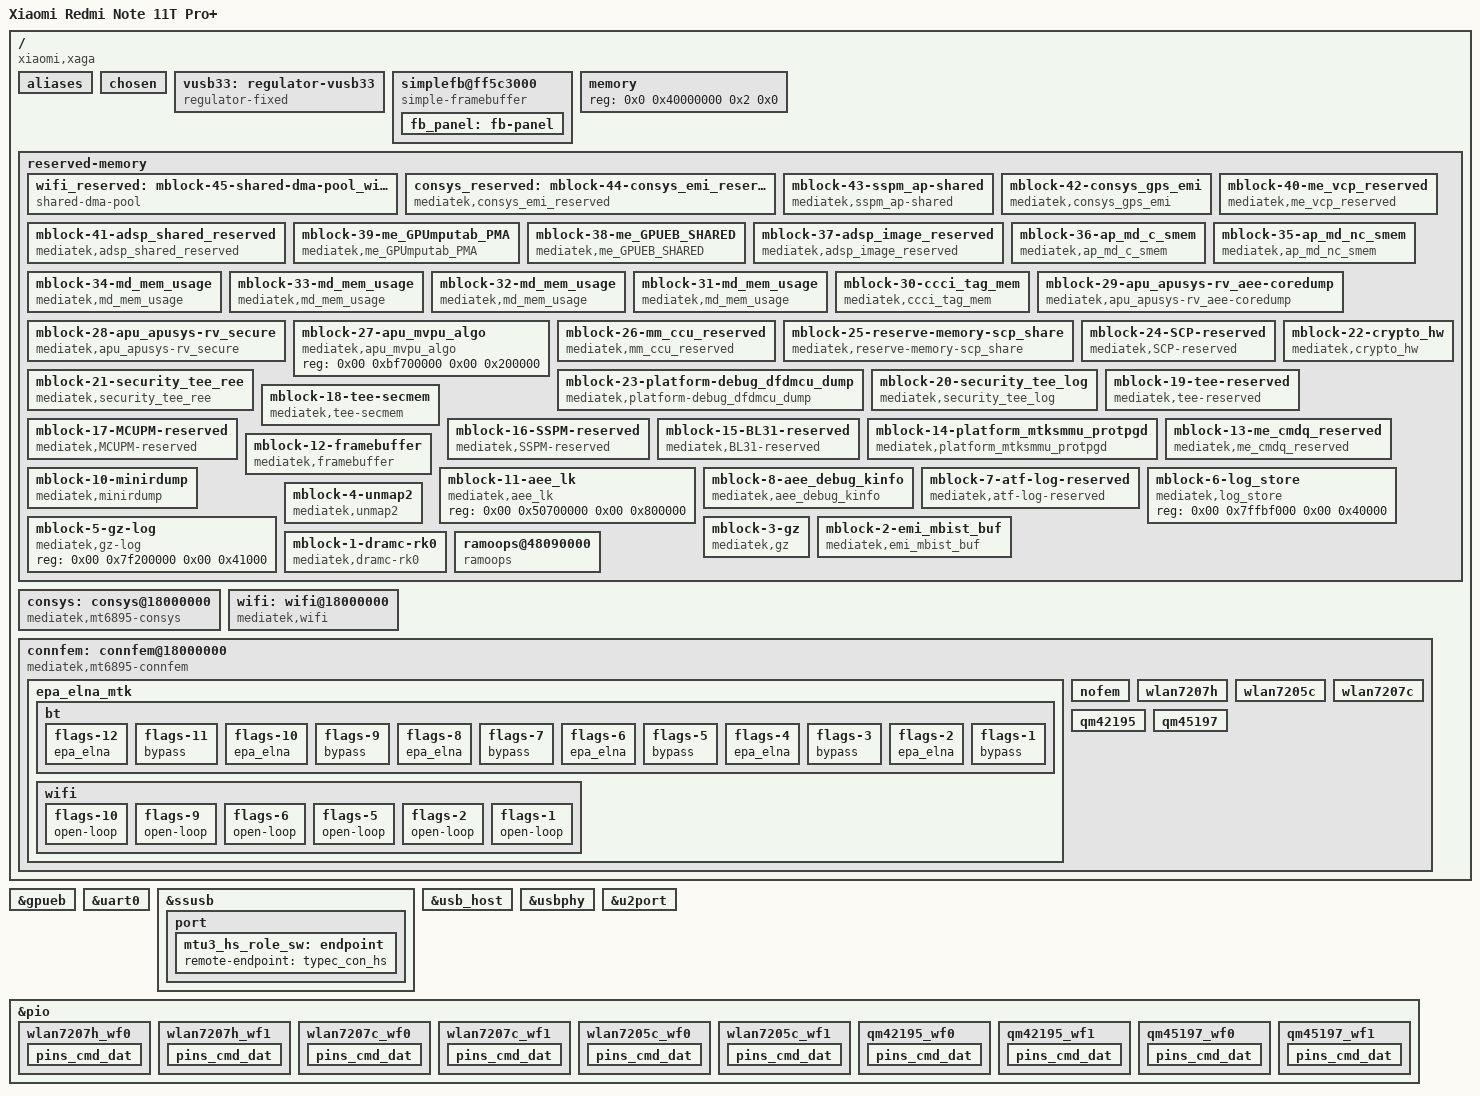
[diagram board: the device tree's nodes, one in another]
// SPDX-License-Identifier: GPL-2.0 OR MIT
/*
 * MT6895 (MediaTek Dimensity 8100) Xiaomi Redmi Note 11T Pro+ board
 *
 * Codename: xaga
 */

/dts-v1/;
#include "mt6895.dtsi"
#include <dt-bindings/input/input.h>
#include <dt-bindings/gpio/gpio.h>

/ {
	model = "Xiaomi Redmi Note 11T Pro+";
	chassis-type = "handset";
	compatible = "xiaomi,xaga", "mediatek,mt6895";

	#address-cells = <2>;
	#size-cells = <2>;

	aliases {
		serial0 = &uart0;
		/* match stock bus numbering so mt6375 etc. land on i2c-5 */
		i2c1 = &i2c1;
		i2c5 = &i2c5;
		i2c6 = &i2c6;
		i2c7 = &i2c7;
	};

	chosen {
		/*
		 * XAGA cmdline: setup.c re-reads /chosen/bootargs from THIS
		 * embedded DTB (early_init_dt_scan_chosen) because LK passes its
		 * own baked-in cmdline (setup_machine_fdt captured it before the
		 * DTB override) and ignores boot.img / vendor_boot cmdlines.
		 * printk.devkmsg=on: /dev/kmsg writes default to a 10-per-5s
		 * ratelimit that was silently dropping cinit's bursty GPT/diag
		 * output (also patched in kernel/printk/printk.c default).
		 * NOTE: console=ttyGS0 is DELIBERATELY absent — its CON_PRINTBUFFER
		 * console kept replaying the whole ring (USB re-enumeration),
		 * looping the log and stalling boot. The cinit shell still works
		 * (it writes directly to /dev/ttyGS0, no console param needed).
		 */
		bootargs = "8250.nr_uarts=4 clk_ignore_unused console=tty0 printk.devkmsg=on log_buf_len=2M";
		/*
		 * LK injects this tag into its FDT; our embedded-DTB override would
		 * lose it. Values dumped from the working Android device:
		 * struct tag_videolfb { u64 fb_base; u32 islcmfound; u32 fps;
		 *                      u32 vram; char lcmname[]; } (LE)
		 * fb_base=0xfe14f000 (framebuffer region start), islcmfound=1,
		 * fps=6060 (x100), vram=0x1eb0000, lcmname="l16_36_02_0b_dsc_vdo_lcm_drv".
		 * Without it, mtk_crtc_fill_fb_para() fails and the LK framebuffer is
		 * never inserted into the display IOMMU -> OVL fetch fault -> RDMA
		 * underflow -> display pipeline stalls after the LK frame.
		 */
		atag,videolfb = [00 f0 14 fe 00 00 00 00 01 00 00 00 ac 17 00 00
				 00 00 eb 01 6c 31 36 5f 33 36 5f 30 32 5f 30 62
				 5f 64 73 63 5f 76 64 6f 5f 6c 63 6d 5f 64 72 76
				 00 60 ff 50];
	};

	/* USB gadget 3.3V rail (mtu3 requires vusb33-supply; LK powers it) */
	vusb33: regulator-vusb33 {
		compatible = "regulator-fixed";
		regulator-name = "vusb33";
		regulator-min-microvolt = <3300000>;
		regulator-max-microvolt = <3300000>;
		regulator-always-on;
	};

	/*
	 * simple-framebuffer left behind by LK. Placed at root level (not under
	 * /chosen) because LK rewrites /chosen and would drop it.
	 * Address = the actual LK scanout layer (mt_disp_config_fb_layer =
	 * 0xff5c3000), which sits inside the reserved mblock-12-framebuffer
	 * region (0xfe14f000..0xfffff000). fbcon draws into the live LK buffer.
	 */
	simplefb@ff5c3000 {
		compatible = "simple-framebuffer";
		/* frame = stride(4352) * height(2460) = 0xa35c00; stays inside the
		 * no-map mblock-12-framebuffer region (0xfe14f000..0xfffff000) */
		reg = <0x0 0xff5c3000 0x0 0xa3c000>;
		width = <1080>;
		height = <2460>;
		stride = <(1088 * 4)>;
		format = "a8r8g8b8";
		panel = <&fb_panel>;

		fb_panel: fb-panel {
			width-mm = <75>;
			height-mm = <166>;
		};
	};

	memory {
		device_type = "memory";
		reg = <0x0 0x40000000 0x2 0x0>;
	};

	reserved-memory {
		#address-cells = <2>;
		#size-cells = <2>;
		ranges;

		/*
		 * Full MT6895 reserved-memory layout, taken verbatim from the
		 * live device tree (/sys/firmware/fdt) of the running stock
		 * Android build. These regions are owned by ATF/TEE/SCP/SSPM,
		 * modem, GPU and the display; the kernel MUST NOT allocate from
		 * them or early boot crashes on memory corruption.
		 */

		wifi_reserved: mblock-45-shared-dma-pool_wifi-reserve-memory_dma {
			reg = <0x00 0xbd000000 0x00 0x1400000>;
			no-map;
			compatible = "shared-dma-pool";
		};
		consys_reserved: mblock-44-consys_emi_reserved {
			reg = <0x00 0x8e500000 0x00 0x800000>;
			no-map;
			compatible = "mediatek,consys_emi_reserved";
		};
		mblock-43-sspm_ap-shared {
			reg = <0x00 0x7c4f0000 0x00 0x110000>;
			no-map;
			compatible = "mediatek,sspm_ap-shared";
		};
		mblock-42-consys_gps_emi {
			reg = <0x00 0x7cf00000 0x00 0x100000>;
			no-map;
			compatible = "mediatek,consys_gps_emi";
		};
		mblock-41-adsp_shared_reserved {
			reg = <0x00 0xf8000000 0x00 0x660000>;
			no-map;
			compatible = "mediatek,adsp_shared_reserved";
		};
		mblock-40-me_vcp_reserved {
			reg = <0x00 0xbee00000 0x00 0x800000>;
			no-map;
			compatible = "mediatek,me_vcp_reserved";
		};
		mblock-39-me_GPUmputab_PMA {
			reg = <0x00 0x78c00000 0x00 0x1400000>;
			no-map;
			compatible = "mediatek,me_GPUmputab_PMA";
		};
		mblock-38-me_GPUEB_SHARED {
			reg = <0x00 0x7c600000 0x00 0x200000>;
			no-map;
			compatible = "mediatek,me_GPUEB_SHARED";
		};
		mblock-37-adsp_image_reserved {
			reg = <0x00 0x7a000000 0x00 0x1230000>;
			no-map;
			compatible = "mediatek,adsp_image_reserved";
		};
		mblock-36-ap_md_c_smem {
			reg = <0x00 0x8a000000 0x00 0x2360000>;
			no-map;
			compatible = "mediatek,ap_md_c_smem";
		};
		mblock-35-ap_md_nc_smem {
			reg = <0x00 0x8e000000 0x00 0x120000>;
			no-map;
			compatible = "mediatek,ap_md_nc_smem";
		};
		mblock-34-md_mem_usage {
			reg = <0x00 0xed6e0000 0x00 0x920000>;
			no-map;
			compatible = "mediatek,md_mem_usage";
		};
		mblock-33-md_mem_usage {
			reg = <0x00 0xd4000000 0x00 0x7870000>;
			no-map;
			compatible = "mediatek,md_mem_usage";
		};
		mblock-32-md_mem_usage {
			reg = <0x00 0xd3000000 0x00 0x240000>;
			no-map;
			compatible = "mediatek,md_mem_usage";
		};
		mblock-31-md_mem_usage {
			reg = <0x00 0xd0000000 0x00 0x2710000>;
			no-map;
			compatible = "mediatek,md_mem_usage";
		};
		mblock-30-ccci_tag_mem {
			reg = <0x00 0xbf6f0000 0x00 0x10000>;
			no-map;
			compatible = "mediatek,ccci_tag_mem";
		};
		mblock-29-apu_apusys-rv_aee-coredump {
			reg = <0x00 0x8ed90000 0x00 0x270000>;
			no-map;
			compatible = "mediatek,apu_apusys-rv_aee-coredump";
		};
		mblock-28-apu_apusys-rv_secure {
			reg = <0x00 0x8f900000 0x00 0x700000>;
			no-map;
			compatible = "mediatek,apu_apusys-rv_secure";
		};
		mblock-27-apu_mvpu_algo {
			reg = <0x00 0xbf700000 0x00 0x200000>;
			compatible = "mediatek,apu_mvpu_algo";
		};
		mblock-26-mm_ccu_reserved {
			reg = <0x00 0x80000000 0x00 0x100000>;
			no-map;
			compatible = "mediatek,mm_ccu_reserved";
		};
		mblock-25-reserve-memory-scp_share {
			reg = <0x00 0x8f000000 0x00 0x6a2000>;
			no-map;
			compatible = "mediatek,reserve-memory-scp_share";
		};
		mblock-24-SCP-reserved {
			reg = <0x00 0xbf900000 0x00 0x500000>;
			no-map;
			compatible = "mediatek,SCP-reserved";
		};
		mblock-23-platform-debug_dfdmcu_dump {
			reg = <0x00 0xfd000000 0x00 0x280000>;
			no-map;
			compatible = "mediatek,platform-debug_dfdmcu_dump";
		};
		mblock-22-crypto_hw {
			reg = <0x00 0x48401000 0x00 0x1000>;
			no-map;
			compatible = "mediatek,crypto_hw";
		};
		mblock-21-security_tee_ree {
			reg = <0x02 0x3f000000 0x00 0xc00000>;
			no-map;
			compatible = "mediatek,security_tee_ree";
		};
		mblock-20-security_tee_log {
			reg = <0x02 0x3fc00000 0x00 0x20000>;
			no-map;
			compatible = "mediatek,security_tee_log";
		};
		mblock-19-tee-reserved {
			reg = <0x00 0x70000000 0x00 0x6000000>;
			no-map;
			compatible = "mediatek,tee-reserved";
		};
		mblock-18-tee-secmem {
			reg = <0x00 0x7c800000 0x00 0x700000>;
			no-map;
			compatible = "mediatek,tee-secmem";
		};
		mblock-17-MCUPM-reserved {
			reg = <0x00 0x7f300000 0x00 0x100000>;
			no-map;
			compatible = "mediatek,MCUPM-reserved";
		};
		mblock-16-SSPM-reserved {
			reg = <0x00 0x7fe3f000 0x00 0x180000>;
			no-map;
			compatible = "mediatek,SSPM-reserved";
		};
		mblock-15-BL31-reserved {
			reg = <0x00 0x48200000 0x00 0x200000>;
			no-map;
			compatible = "mediatek,BL31-reserved";
		};
		mblock-14-platform_mtksmmu_protpgd {
			reg = <0x00 0x7d000000 0x00 0x2200000>;
			no-map;
			compatible = "mediatek,platform_mtksmmu_protpgd";
		};
		mblock-13-me_cmdq_reserved {
			reg = <0x02 0x3fe00000 0x00 0x100000>;
			no-map;
			compatible = "mediatek,me_cmdq_reserved";
		};
		mblock-12-framebuffer {
			reg = <0x00 0xfe14f000 0x00 0x1eb0000>;
			/*
			 * no-map: this region (which contains the live LK scanout
			 * framebuffer at 0xff5c3000) must be excluded from the
			 * kernel's RAM map. Otherwise simplefb's
			 * request_mem_region()/ioremap() fail (-ENOMEM, "cannot
			 * reserve video memory" / ioremap_p2p WARN).
			 */
			no-map;
			compatible = "mediatek,framebuffer";
		};
		mblock-11-aee_lk {
			reg = <0x00 0x50700000 0x00 0x800000>;
			compatible = "mediatek,aee_lk";
		};
		mblock-10-minirdump {
			reg = <0x00 0x48170000 0x00 0x10000>;
			no-map;
			compatible = "mediatek,minirdump";
		};
		mblock-8-aee_debug_kinfo {
			reg = <0x00 0x48080000 0x00 0x10000>;
			no-map;
			compatible = "mediatek,aee_debug_kinfo";
		};
		mblock-7-atf-log-reserved {
			reg = <0x00 0xbfe00000 0x00 0x200000>;
			no-map;
			compatible = "mediatek,atf-log-reserved";
		};
		mblock-6-log_store {
			reg = <0x00 0x7ffbf000 0x00 0x40000>;
			compatible = "mediatek,log_store";
		};
		mblock-5-gz-log {
			reg = <0x00 0x7f200000 0x00 0x41000>;
			compatible = "mediatek,gz-log";
		};
		mblock-4-unmap2 {
			reg = <0x00 0x7f400000 0x00 0x400000>;
			no-map;
			compatible = "mediatek,unmap2";
		};
		mblock-3-gz {
			reg = <0x00 0x7f800000 0x00 0x600000>;
			no-map;
			compatible = "mediatek,gz";
		};
		mblock-2-emi_mbist_buf {
			reg = <0x00 0x7ffff000 0x00 0x1000>;
			no-map;
			compatible = "mediatek,emi_mbist_buf";
		};
		mblock-1-dramc-rk0 {
			reg = <0x02 0x3fffe000 0x00 0x2000>;
			no-map;
			compatible = "mediatek,dramc-rk0";
		};
		/* pstore/ramoops, matches the downstream Android config */
		ramoops@48090000 {
			compatible = "ramoops";
			reg = <0x00 0x48090000 0x00 0xe0000>;
			record-size = <0x20000>;
			console-size = <0x40000>;
			pmsg-size = <0x10000>;
			ecc-size = <0>;
			no-map;
		};
	};

	/* MediaTek CONNAC2X2 SOC7_0 connectivity: consys / wifi / connfem.
	 * Nodes and properties copied from downstream mt6895.dts and
	 * cust_mt6895_connfem.dtsi.  memory-region references are added so the
	 * downstream fullmac driver can find the reserved EMI/DMA areas without
	 * depending on LK runtime fixups.
	 */
	consys: consys@18000000 {
		compatible = "mediatek,mt6895-consys";
		#thermal-sensor-cells = <0>;
		reg = <0x00 0x10001000 0x00 0xee4 0x00 0x10005000 0x00 0xa78
		       0x00 0x11c30000 0x00 0xa14 0x00 0x11ea0000 0x00 0xa04
		       0x00 0x18000000 0x00 0x470 0x00 0x18001000 0x00 0x658
		       0x00 0x18003000 0x00 0x204 0x00 0x1800e000 0x00 0x124
		       0x00 0x18011000 0x00 0x138 0x00 0x18012000 0x00 0x98
		       0x00 0x18020000 0x00 0x4c 0x00 0x18023000 0x00 0xe28
		       0x00 0x1803b000 0x00 0x18 0x00 0x18040000 0x00 0x2c
		       0x00 0x18041000 0x00 0x128 0x00 0x18042000 0x00 0x324
		       0x00 0x1804b000 0x00 0x414 0x00 0x1804d000 0x00 0x41c
		       0x00 0x1804f000 0x00 0x148 0x00 0x18053800 0x00 0x1000
		       0x00 0x18060000 0x00 0xc08 0x00 0x18070000 0x00 0x8004
		       0x00 0x1c001000 0x00 0xfb0 0x00 0x1c007000 0x00 0x51c>;
		power-domains = <&spm MT6895_POWER_DOMAIN_CONN>;
		mt6363_vcn13-supply = <&mt6363_vcn13>;
		mt6363_vrfio18-supply = <&mt6363_vrfio18>;
		mt6368_vcn33_1-supply = <&mt6368_vcn33_1>;
		mt6368_vcn33_2-supply = <&mt6368_vcn33_2>;
		mt6368_vant18-supply = <&mt6368_vant18>;
		memory-region = <&consys_reserved>;
		emi-addr = <0>;
		emi-size = <0x7e0000>;
		emi-alignment = <0x100000>;
		emi-max-addr = <0x90000000>;
		tcxo_support = "false";
		scp-shm-addr = <0>;
		scp-shm-size = <0x20000>;
		status = "okay";
	};

	wifi: wifi@18000000 {
		compatible = "mediatek,wifi";
		reg = <0x0 0x18000000 0x0 0x700000>;
		interrupts = <GIC_SPI 522 IRQ_TYPE_LEVEL_HIGH 0>,
			     <GIC_SPI 537 IRQ_TYPE_LEVEL_HIGH 0>;
		memory-region = <&wifi_reserved>;
		flavor_bin = "b_t";
		emi-addr = <0>;
		emi-size = <0x1400000>;
		emi-alignment = <0x1000000>;
		emi-max-addr = <0xC0000000>;
		status = "okay";
	};

	connfem: connfem@18000000 {
		compatible = "mediatek,mt6895-connfem";
		pinctrl-names = "wlan7207h_wlan7207c",
				"wlan7207h_wlan7205c",
				"qm42195_qm45197";
		pinctrl-0 = <&wlan7207h_wf0>, <&wlan7207h_wf1>,
			    <&wlan7207c_wf0>, <&wlan7207c_wf1>;
		pinctrl-1 = <&wlan7207h_wf0>, <&wlan7207h_wf1>,
			    <&wlan7205c_wf0>, <&wlan7205c_wf1>;
		pinctrl-2 = <&qm42195_wf0>, <&qm42195_wf1>,
			    <&qm45197_wf0>, <&qm45197_wf1>;
		status = "okay";

		epa_elna_mtk {
			parts = <&nofem &nofem>,
				<&wlan7207h &wlan7207c>,
				<&wlan7207h &wlan7207c>,
				<&wlan7207h &wlan7207c>,
				<&wlan7207h &wlan7207c>,
				<&wlan7207h &wlan7205c>,
				<&wlan7207h &wlan7205c>,
				<&wlan7207h &wlan7205c>,
				<&wlan7207h &wlan7205c>,
				<&qm42195 &qm45197>,
				<&qm42195 &qm45197>,
				<&qm42195 &qm45197>,
				<&qm42195 &qm45197>;

			bt {
				flags-12 { epa_elna; };
				flags-11 { bypass; };
				flags-10 { epa_elna; };
				flags-9 { bypass; };
				flags-8 { epa_elna; };
				flags-7 { bypass; };
				flags-6 { epa_elna; };
				flags-5 { bypass; };
				flags-4 { epa_elna; };
				flags-3 { bypass; };
				flags-2 { epa_elna; };
				flags-1 { bypass; };
			};

			wifi {
				flags-10 { open-loop; };
				flags-9 { open-loop; };
				flags-6 { open-loop; };
				flags-5 { open-loop; };
				flags-2 { open-loop; };
				flags-1 { open-loop; };
			};
		};

		nofem: nofem {
			vid = <0>;
			pid = <0>;
		};

		wlan7207h: wlan7207h {
			vid = <2>;
			pid = <4>;
		};

		wlan7205c: wlan7205c {
			vid = <2>;
			pid = <5>;
		};

		wlan7207c: wlan7207c {
			vid = <2>;
			pid = <7>;
		};

		qm42195: qm42195 {
			vid = <3>;
			pid = <1>;
		};

		qm45197: qm45197 {
			vid = <3>;
			pid = <2>;
		};
	};
};

/* GPUEB shared memory: the live FDT reserves 2MB at 0x7c600000 as
 * mblock-38-me_GPUEB_SHARED. gpueb_reserved_mem.c can use it directly
 * when gpueb_mem_addr/size are present on the gpueb node.
 */
&gpueb {
	gpueb_mem_addr = <0x0 0x7c600000>;
	gpueb_mem_size = <0x0 0x200000>;
};

&uart0 {
	status = "okay";
};

/*
 * The mediatek_v2 display driver (binds on dispsys_config@14000000) is now
 * active. The LK frame stays visible via simplefb above until the DRM driver
 * takes over. Keep simplefb enabled during bring-up as a fallback.
 */

/*
 * USB manual OTG:
 * - dr_mode="otg" keeps both host and device paths available.
 * - usb-role-switch + role-switch-default-mode="device" expose a sysfs role
 *   switch for manual host/device selection (no automatic Type-C detect yet).
 * - vbus-supply is the MT6375 charger OTG regulator needed to source 5V in
 *   host mode.
 * - The t-phy software role switch is kept, and role-switch-default-mode="device"
 *   is set on the xHCI node so the PHY initializes in device mode.
 */

&ssusb {
	status = "okay";
	dr_mode = "otg";
	maximum-speed = "high-speed";
	usb-role-switch;
	role-switch-default-mode = "device";
	vusb33-supply = <&vusb33>;
	vbus-supply = <&otg_vbus>;

	port {
		mtu3_hs_role_sw: endpoint {
			remote-endpoint = <&typec_con_hs>;
		};
	};
};

&usb_host {
	status = "okay";
	role-switch-default-mode = "device";
	vusb33-supply = <&vusb33>;
};

&usbphy {
	status = "okay";
};

&u2port {
	status = "okay";
	/* PHY tuning from downstream xaga DTS */
	mediatek,eye-vrt = <0x03>;
	mediatek,eye-term = <0x03>;
	mediatek,discth = <0x0b>;
};

/* ConnFem ANTSEL pinmux and FEM function mapping */
&pio {
	wlan7207h_wf0: wlan7207h_wf0 {
		pins_cmd_dat {
			pinmux = <PINMUX_GPIO176__FUNC_ANT_SEL0>,
				<PINMUX_GPIO177__FUNC_ANT_SEL1>,
				<PINMUX_GPIO178__FUNC_ANT_SEL2>,
				<PINMUX_GPIO179__FUNC_ANT_SEL3>;
			mapping = <0 3 0>,	/* ANTSEL 0 <-> PIN #3: C0 */
				<1 2 0>,	/* ANTSEL 1 <-> PIN #2: C1 */
				<2 4 0>,	/* ANTSEL 2 <-> PIN #4: C2 */
				<3 11 0>;	/* ANTSEL 3 <-> VCTRL */
		};
	};

	wlan7207h_wf1: wlan7207h_wf1 {
		pins_cmd_dat {
			pinmux = <PINMUX_GPIO184__FUNC_ANT_SEL8>,
				<PINMUX_GPIO185__FUNC_ANT_SEL9>,
				<PINMUX_GPIO188__FUNC_ANT_SEL10>;
			mapping = <8 0x83 0>,	/* ANTSEL  8 <-> PIN #3: C0 */
				<9 0x82 0>,	/* ANTSEL  9 <-> PIN #2: C1 */
				<10 0x84 0>;	/* ANTSEL 10 <-> PIN #4: C2 */
		};
	};

	wlan7207c_wf0: wlan7207c_wf0 {
		pins_cmd_dat {
			pinmux = <PINMUX_GPIO180__FUNC_ANT_SEL4>,
				<PINMUX_GPIO76__FUNC_ANT_SEL20>,
				<PINMUX_GPIO182__FUNC_ANT_SEL6>,
				<PINMUX_GPIO183__FUNC_ANT_SEL7>;
			mapping = <4 0x4A 0>,	/* ANTSEL  4 <-> PIN #12: C0 */
				<20 0x4B 0>,	/* ANTSEL 20 <-> PIN #13: C1 */
				<6 0x4C 0>,	/* ANTSEL  6 <-> PIN #14: C2 */
				<7 0x41 0>;	/* ANTSEL  7 <-> PIN #11: C3 */
		};
	};

	wlan7207c_wf1: wlan7207c_wf1 {
		pins_cmd_dat {
			pinmux = <PINMUX_GPIO189__FUNC_ANT_SEL11>,
				<PINMUX_GPIO77__FUNC_ANT_SEL21>,
				<PINMUX_GPIO190__FUNC_ANT_SEL12>,
				<PINMUX_GPIO181__FUNC_ANT_SEL5>;
			mapping = <11 0xCA 0>,	/* ANTSEL 11 <-> PIN #12: C0 */
				<21 0xCB 0>,	/* ANTSEL 21 <-> PIN #13: C1 */
				<12 0xCC 0>,	/* ANTSEL 12 <-> PIN #14: C2 */
				<5 0xC1 0>;	/* ANTSEL  5 <-> PIN #11: C3 */
		};
	};

	wlan7205c_wf0: wlan7205c_wf0 {
		pins_cmd_dat {
			pinmux = <PINMUX_GPIO180__FUNC_ANT_SEL4>,
				<PINMUX_GPIO76__FUNC_ANT_SEL20>,
				<PINMUX_GPIO182__FUNC_ANT_SEL6>,
				<PINMUX_GPIO183__FUNC_ANT_SEL7>;
			mapping = <4 0x4C 0>,	/* ANTSEL  4 <-> PIN #12: C0 */
				<20 0x4D 0>,	/* ANTSEL 20 <-> PIN #13: C1 */
				<6 0x4E 0>,	/* ANTSEL  6 <-> PIN #14: C2 */
				<7 0x4B 0>;	/* ANTSEL  7 <-> PIN #11: C3 */
		};
	};

	wlan7205c_wf1: wlan7205c_wf1 {
		pins_cmd_dat {
			pinmux = <PINMUX_GPIO189__FUNC_ANT_SEL11>,
				<PINMUX_GPIO77__FUNC_ANT_SEL21>,
				<PINMUX_GPIO190__FUNC_ANT_SEL12>,
				<PINMUX_GPIO181__FUNC_ANT_SEL5>;
			mapping = <11 0xCC 0>,	/* ANTSEL 11 <-> PIN #12: C0 */
				<21 0xCD 0>,	/* ANTSEL 21 <-> PIN #13: C1 */
				<12 0xCE 0>,	/* ANTSEL 12 <-> PIN #14: C2 */
				<5 0xCB 0>;	/* ANTSEL  5 <-> PIN #11: C3 */
		};
	};

	qm42195_wf0: qm42195_wf0 {
		pins_cmd_dat {
			pinmux = <PINMUX_GPIO176__FUNC_ANT_SEL0>,
				<PINMUX_GPIO177__FUNC_ANT_SEL1>,
				<PINMUX_GPIO178__FUNC_ANT_SEL2>,
				<PINMUX_GPIO179__FUNC_ANT_SEL3>;
			mapping = <0 3 0>,	/* ANTSEL 0 <-> PIN #3: PAEN */
				<1 2 0>,	/* ANTSEL 1 <-> PIN #2: LNAEN */
				<2 4 0>,	/* ANTSEL 2 <-> PIN #4: BTEN */
				<3 11 0>;	/* ANTSEL 3 <-> VCTRL */
		};
	};

	qm42195_wf1: qm42195_wf1 {
		pins_cmd_dat {
			pinmux = <PINMUX_GPIO184__FUNC_ANT_SEL8>,
				<PINMUX_GPIO185__FUNC_ANT_SEL9>,
				<PINMUX_GPIO188__FUNC_ANT_SEL10>;
			mapping = <8 0x83 0>,	/* ANTSEL  8 <-> PIN #3: PAEN */
				<9 0x82 0>,	/* ANTSEL  9 <-> PIN #2: LNAEN */
				<10 0x84 0>;	/* ANTSEL 10 <-> PIN #4: BTEN */
		};
	};

	qm45197_wf0: qm45197_wf0 {
		pins_cmd_dat {
			pinmux = <PINMUX_GPIO180__FUNC_ANT_SEL4>,
				<PINMUX_GPIO76__FUNC_ANT_SEL20>,
				<PINMUX_GPIO182__FUNC_ANT_SEL6>;
			mapping = <4 0x4A 0>,	/* ANTSEL  4 <-> PIN #10: PAEN */
				<20 0x4B 0>,	/* ANTSEL 20 <-> PIN #11: LNAEN */
				<6 0x4C 0>;	/* ANTSEL  6 <-> PIN #12: SEL3 */
		};
	};

	qm45197_wf1: qm45197_wf1 {
		pins_cmd_dat {
			pinmux = <PINMUX_GPIO189__FUNC_ANT_SEL11>,
				<PINMUX_GPIO77__FUNC_ANT_SEL21>,
				<PINMUX_GPIO190__FUNC_ANT_SEL12>;
			mapping = <11 0xCA 0>,	/* ANTSEL 11 <-> PIN #10: PAEN */
				<21 0xCB 0>,	/* ANTSEL 21 <-> PIN #11: LNAEN */
				<12 0xCC 0>;	/* ANTSEL 12 <-> PIN #12: SEL3 */
		};
	};
};
